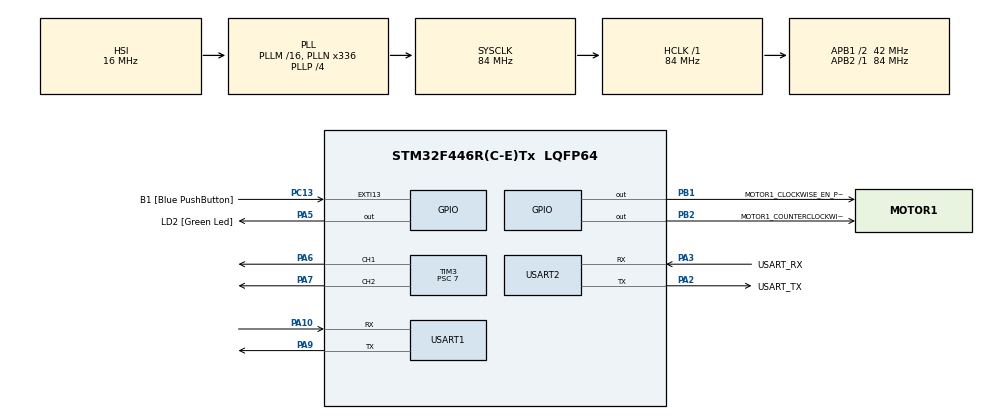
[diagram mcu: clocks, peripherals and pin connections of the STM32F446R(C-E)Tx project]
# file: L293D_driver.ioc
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Mcu.Family=STM32F4
PH0-OSC_IN.Signal=RCC_OSC_IN
RCC.CortexFreq_Value=84000000
PA14.GPIO_Label=TCK
PC13.GPIO_Label=B1 [Blue PushButton]
RCC.SYSCLKSource=RCC_SYSCLKSOURCE_PLLCLK
ProjectManager.StackSize=0x400
RCC.HCLKFreq_Value=84000000
RCC.APB2TimFreq_Value=84000000
TIM3.Period=420
RCC.AHBFreq_Value=84000000
PH0-OSC_IN.Mode=HSE-External-Oscillator
TIM3.Channel-PWM\ Generation1\ CH1=TIM_CHANNEL_1
RCC.HSE_VALUE=8000000
PB2.Signal=GPIO_Output
PC14-OSC32_IN.Mode=LSE-External-Oscillator
PA14.Mode=Serial_Wire
TIM3.Prescaler=7
PB1.GPIO_Label=MOTOR1_CLOCKWISE_EN_PIN
SH.S_TIM3_CH1.0=TIM3_CH1,PWM Generation1 CH1
RCC.FLatency-AdvancedSettings=FLASH_LATENCY_2
PH1-OSC_OUT.Mode=HSE-External-Oscillator
Mcu.Package=LQFP64
PA6.Signal=S_TIM3_CH1
PB1.Signal=GPIO_Output
USART2.VirtualMode=VM_ASYNC
PA2.GPIO_Label=USART_TX
PA10.Signal=USART1_RX
RCC.APB1TimFreq_Value=84000000
TIM3.Pulse-PWM\ Generation2\ CH2=330
PA3.Signal=USART2_RX
PB3.GPIO_Label=SWO
PC15-OSC32_OUT.Mode=LSE-External-Oscillator
PA10.Mode=Asynchronous
PC13.Signal=GPXTI13
RCC.APB1CLKDivider=RCC_HCLK_DIV2
PC14-OSC32_IN.Signal=RCC_OSC32_IN
PA13.Signal=SYS_JTMS-SWDIO
PA3.Mode=Asynchronous
PA9.Mode=Asynchronous
TIM3.Pulse-PWM\ Generation1\ CH1=110
ProjectManager.TargetToolchain=STM32CubeIDE
PA9.Signal=USART1_TX
RCC.USBFreq_Value=168000000
PC15-OSC32_OUT.Signal=RCC_OSC32_OUT
PA5.Signal=GPIO_Output
SH.S_TIM3_CH2.0=TIM3_CH2,PWM Generation2 CH2
board=NUCLEO-F446RE
RCC.VCOOutputFreq_Value=336000000
RCC.APB2Freq_Value=84000000
PH1-OSC_OUT.Signal=RCC_OSC_OUT
PA13.Mode=Serial_Wire
Mcu.Name=STM32F446R(C-E)Tx
PA13.GPIO_Label=TMS
PA2.Signal=USART2_TX
RCC.48MHZClocksFreq_Value=84000000
PB3.Signal=SYS_JTDO-SWO
RCC.SYSCLKFreq_VALUE=84000000
PA5.GPIO_Label=LD2 [Green Led]
PC13.GPIO_ModeDefaultEXTI=GPIO_MODE_IT_FALLING
USART1.VirtualMode=VM_ASYNC
PA14.Signal=SYS_JTCK-SWCLK
PB2.GPIO_Label=MOTOR1_COUNTERCLOCKWISE_EN_PIN
ProjectManager.HeapSize=0x200
RCC.HSI_VALUE=16000000
RCC.PLLP=RCC_PLLP_DIV4
NVIC.PriorityGroup=NVIC_PRIORITYGROUP_0
TIM3.Channel-PWM\ Generation2\ CH2=TIM_CHANNEL_2
RCC.PLLN=336
PA2.Mode=Asynchronous
RCC.APB1Freq_Value=42000000
PA3.GPIO_Label=USART_RX
PA7.Signal=S_TIM3_CH2

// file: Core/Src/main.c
/* USER CODE BEGIN Header */
/**
  ******************************************************************************
  * @file           : main.c
  * @brief          : Main program body
  ******************************************************************************
  * @attention
  *
  * <h2><center>&copy; Copyright (c) 2023 STMicroelectronics.
  * All rights reserved.</center></h2>
  *
  * This software component is licensed by ST under BSD 3-Clause license,
  * the "License"; You may not use this file except in compliance with the
  * License. You may obtain a copy of the License at:
  *                        opensource.org/licenses/BSD-3-Clause
  *
  ******************************************************************************
  */
/* USER CODE END Header */
#include "main.h"

/* USER CODE BEGIN Includes */
#include <string.h>
#include <stdio.h>
/* USER CODE END Includes */

TIM_HandleTypeDef htim3;

UART_HandleTypeDef huart1;
UART_HandleTypeDef huart2;

/* USER CODE BEGIN PV */
volatile uint32_t pulse;
char message[60];
/* USER CODE END PV */

void SystemClock_Config(void);
static void MX_GPIO_Init(void);
static void MX_TIM3_Init(void);
static void MX_USART1_UART_Init(void);
static void MX_USART2_UART_Init(void);

int main(void)
{

  /* MCU Configuration--------------------------------------------------------*/

  /* Reset of all peripherals, Initializes the Flash interface and the Systick. */
  HAL_Init();

  /* Configure the system clock */
  SystemClock_Config();

  /* Initialize all configured peripherals */
  MX_GPIO_Init();
  MX_TIM3_Init();
  MX_USART1_UART_Init();
  MX_USART2_UART_Init();
  /* USER CODE BEGIN 2 */
  struct L293D_motor_t left_motor;

  L293D_motor_init(&left_motor, &htim3, TIM_CHANNEL_1, MOTOR1_CLOCKWISE_EN_PIN_Pin,
		  MOTOR1_COUNTERCLOCKWISE_EN_PIN_Pin, GPIOB, GPIOB);
  select_motor_rotation_direction(&left_motor, MOTOR_ROTATION_CLOCKWISE);
  EnorDi_pwm_signal(&left_motor, ENABLE);

  /* USER CODE END 2 */

  /* Infinite loop */
  while (1)
  {
	  select_motor_rotation_direction(&left_motor, MOTOR_ROTATION_CLOCKWISE);
	  HAL_Delay(3000);

	  sprintf(message, "Pulse: %d, dir: %d \n\r", (int)left_motor.htimer->Instance->CCR1,
	    		  (int)left_motor.direction_of_rotation_flag);
	  HAL_UART_Transmit(&huart2, (uint8_t*)message, strlen(message), 20);

	  select_motor_rotation_direction(&left_motor, MOTOR_ROTATION_COUNTERCLOCKWISE);
	  HAL_Delay(3000);

	  sprintf(message, "Pulse: %d, dir: %d \n\r", (int)left_motor.htimer->Instance->CCR1,
	    		  (int)left_motor.direction_of_rotation_flag);
	  HAL_UART_Transmit(&huart2, (uint8_t*)message, strlen(message), 20);
  }
}

void SystemClock_Config(void)
{
  RCC_OscInitTypeDef RCC_OscInitStruct = {0};
  RCC_ClkInitTypeDef RCC_ClkInitStruct = {0};

  /** Configure the main internal regulator output voltage
  */
  __HAL_RCC_PWR_CLK_ENABLE();
  __HAL_PWR_VOLTAGESCALING_CONFIG(PWR_REGULATOR_VOLTAGE_SCALE3);
  /** Initializes the RCC Oscillators according to the specified parameters
  * in the RCC_OscInitTypeDef structure.
  */
  RCC_OscInitStruct.OscillatorType = RCC_OSCILLATORTYPE_HSI;
  RCC_OscInitStruct.HSIState = RCC_HSI_ON;
  RCC_OscInitStruct.HSICalibrationValue = RCC_HSICALIBRATION_DEFAULT;
  RCC_OscInitStruct.PLL.PLLState = RCC_PLL_ON;
  RCC_OscInitStruct.PLL.PLLSource = RCC_PLLSOURCE_HSI;
  RCC_OscInitStruct.PLL.PLLM = 16;
  RCC_OscInitStruct.PLL.PLLN = 336;
  RCC_OscInitStruct.PLL.PLLP = RCC_PLLP_DIV4;
  RCC_OscInitStruct.PLL.PLLQ = 2;
  RCC_OscInitStruct.PLL.PLLR = 2;
  if (HAL_RCC_OscConfig(&RCC_OscInitStruct) != HAL_OK)
  {
    Error_Handler();
  }
  /** Initializes the CPU, AHB and APB buses clocks
  */
  RCC_ClkInitStruct.ClockType = RCC_CLOCKTYPE_HCLK|RCC_CLOCKTYPE_SYSCLK
                              |RCC_CLOCKTYPE_PCLK1|RCC_CLOCKTYPE_PCLK2;
  RCC_ClkInitStruct.SYSCLKSource = RCC_SYSCLKSOURCE_PLLCLK;
  RCC_ClkInitStruct.AHBCLKDivider = RCC_SYSCLK_DIV1;
  RCC_ClkInitStruct.APB1CLKDivider = RCC_HCLK_DIV2;
  RCC_ClkInitStruct.APB2CLKDivider = RCC_HCLK_DIV1;

  if (HAL_RCC_ClockConfig(&RCC_ClkInitStruct, FLASH_LATENCY_2) != HAL_OK)
  {
    Error_Handler();
  }
}

static void MX_TIM3_Init(void)
{

  TIM_MasterConfigTypeDef sMasterConfig = {0};
  TIM_OC_InitTypeDef sConfigOC = {0};

  htim3.Instance = TIM3;
  htim3.Init.Prescaler = 7;
  htim3.Init.CounterMode = TIM_COUNTERMODE_UP;
  htim3.Init.Period = 420;
  htim3.Init.ClockDivision = TIM_CLOCKDIVISION_DIV1;
  htim3.Init.AutoReloadPreload = TIM_AUTORELOAD_PRELOAD_DISABLE;
  if (HAL_TIM_PWM_Init(&htim3) != HAL_OK)
  {
    Error_Handler();
  }
  sMasterConfig.MasterOutputTrigger = TIM_TRGO_RESET;
  sMasterConfig.MasterSlaveMode = TIM_MASTERSLAVEMODE_DISABLE;
  if (HAL_TIMEx_MasterConfigSynchronization(&htim3, &sMasterConfig) != HAL_OK)
  {
    Error_Handler();
  }
  sConfigOC.OCMode = TIM_OCMODE_PWM1;
  sConfigOC.Pulse = 300;
  sConfigOC.OCPolarity = TIM_OCPOLARITY_HIGH;
  sConfigOC.OCFastMode = TIM_OCFAST_DISABLE;
  if (HAL_TIM_PWM_ConfigChannel(&htim3, &sConfigOC, TIM_CHANNEL_1) != HAL_OK)
  {
    Error_Handler();
  }
  sConfigOC.Pulse = 330;
  if (HAL_TIM_PWM_ConfigChannel(&htim3, &sConfigOC, TIM_CHANNEL_2) != HAL_OK)
  {
    Error_Handler();
  }
  HAL_TIM_MspPostInit(&htim3);

}

static void MX_USART1_UART_Init(void)
{

  huart1.Instance = USART1;
  huart1.Init.BaudRate = 115200;
  huart1.Init.WordLength = UART_WORDLENGTH_8B;
  huart1.Init.StopBits = UART_STOPBITS_1;
  huart1.Init.Parity = UART_PARITY_NONE;
  huart1.Init.Mode = UART_MODE_TX_RX;
  huart1.Init.HwFlowCtl = UART_HWCONTROL_NONE;
  huart1.Init.OverSampling = UART_OVERSAMPLING_16;
  if (HAL_UART_Init(&huart1) != HAL_OK)
  {
    Error_Handler();
  }

}

static void MX_USART2_UART_Init(void)
{

  huart2.Instance = USART2;
  huart2.Init.BaudRate = 115200;
  huart2.Init.WordLength = UART_WORDLENGTH_8B;
  huart2.Init.StopBits = UART_STOPBITS_1;
  huart2.Init.Parity = UART_PARITY_NONE;
  huart2.Init.Mode = UART_MODE_TX_RX;
  huart2.Init.HwFlowCtl = UART_HWCONTROL_NONE;
  huart2.Init.OverSampling = UART_OVERSAMPLING_16;
  if (HAL_UART_Init(&huart2) != HAL_OK)
  {
    Error_Handler();
  }

}

static void MX_GPIO_Init(void)
{
  GPIO_InitTypeDef GPIO_InitStruct = {0};

  /* GPIO Ports Clock Enable */
  __HAL_RCC_GPIOC_CLK_ENABLE();
  __HAL_RCC_GPIOH_CLK_ENABLE();
  __HAL_RCC_GPIOA_CLK_ENABLE();
  __HAL_RCC_GPIOB_CLK_ENABLE();

  /*Configure GPIO pin Output Level */
  HAL_GPIO_WritePin(LD2_GPIO_Port, LD2_Pin, GPIO_PIN_RESET);

  /*Configure GPIO pin Output Level */
  HAL_GPIO_WritePin(GPIOB, MOTOR1_CLOCKWISE_EN_PIN_Pin|MOTOR1_COUNTERCLOCKWISE_EN_PIN_Pin, GPIO_PIN_RESET);

  /*Configure GPIO pin : B1_Pin */
  GPIO_InitStruct.Pin = B1_Pin;
  GPIO_InitStruct.Mode = GPIO_MODE_IT_FALLING;
  GPIO_InitStruct.Pull = GPIO_NOPULL;
  HAL_GPIO_Init(B1_GPIO_Port, &GPIO_InitStruct);

  /*Configure GPIO pin : LD2_Pin */
  GPIO_InitStruct.Pin = LD2_Pin;
  GPIO_InitStruct.Mode = GPIO_MODE_OUTPUT_PP;
  GPIO_InitStruct.Pull = GPIO_NOPULL;
  GPIO_InitStruct.Speed = GPIO_SPEED_FREQ_LOW;
  HAL_GPIO_Init(LD2_GPIO_Port, &GPIO_InitStruct);

  /*Configure GPIO pins : MOTOR1_CLOCKWISE_EN_PIN_Pin MOTOR1_COUNTERCLOCKWISE_EN_PIN_Pin */
  GPIO_InitStruct.Pin = MOTOR1_CLOCKWISE_EN_PIN_Pin|MOTOR1_COUNTERCLOCKWISE_EN_PIN_Pin;
  GPIO_InitStruct.Mode = GPIO_MODE_OUTPUT_PP;
  GPIO_InitStruct.Pull = GPIO_NOPULL;
  GPIO_InitStruct.Speed = GPIO_SPEED_FREQ_LOW;
  HAL_GPIO_Init(GPIOB, &GPIO_InitStruct);

}

void Error_Handler(void)
{
  __disable_irq();
  while (1)
  {
  }
}

/************************ (C) COPYRIGHT STMicroelectronics *****END OF FILE****/
